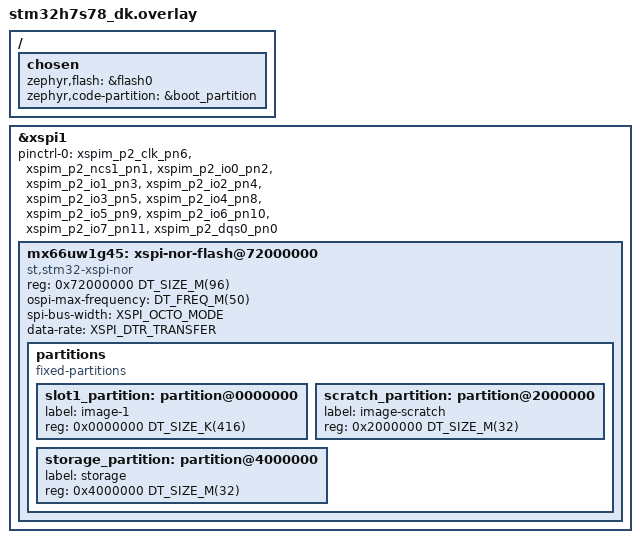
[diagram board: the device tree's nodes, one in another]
/*
 * Copyright (c) 2024 STMicroelectronics
 *
 * SPDX-License-Identifier: Apache-2.0
 */

/ {
	chosen {
		zephyr,flash = &flash0;
		zephyr,code-partition = &boot_partition;
	};
};

&xspi1 {
	/* same pining as xspi2 */
	pinctrl-0 = <&xspim_p2_clk_pn6 &xspim_p2_ncs1_pn1
		     &xspim_p2_io0_pn2 &xspim_p2_io1_pn3
		     &xspim_p2_io2_pn4 &xspim_p2_io3_pn5
		     &xspim_p2_io4_pn8 &xspim_p2_io5_pn9
		     &xspim_p2_io6_pn10 &xspim_p2_io7_pn11
		     &xspim_p2_dqs0_pn0>;
	pinctrl-names = "default";

	status = "okay";

	mx66uw1g45: xspi-nor-flash@72000000 {
		compatible = "st,stm32-xspi-nor";
		reg = <0x72000000 DT_SIZE_M(96)>; /* bank1 - 3*/
		ospi-max-frequency = <DT_FREQ_M(50)>;
		spi-bus-width = <XSPI_OCTO_MODE>;
		data-rate = <XSPI_DTR_TRANSFER>;
		status = "okay";

		partitions {
			compatible = "fixed-partitions";
			#address-cells = <1>;
			#size-cells = <1>;
			/* bank1 */
			slot1_partition: partition@0000000 {
				label = "image-1";
				reg = <0x0000000 DT_SIZE_K(416)>;
			};
			/* bank2 */
			scratch_partition: partition@2000000 {
				label = "image-scratch";
				reg = <0x2000000 DT_SIZE_M(32)>;
			};
			/* bank3 */
			storage_partition: partition@4000000 {
				label = "storage";
				reg = <0x4000000 DT_SIZE_M(32)>;
			};
		};
	};
};

